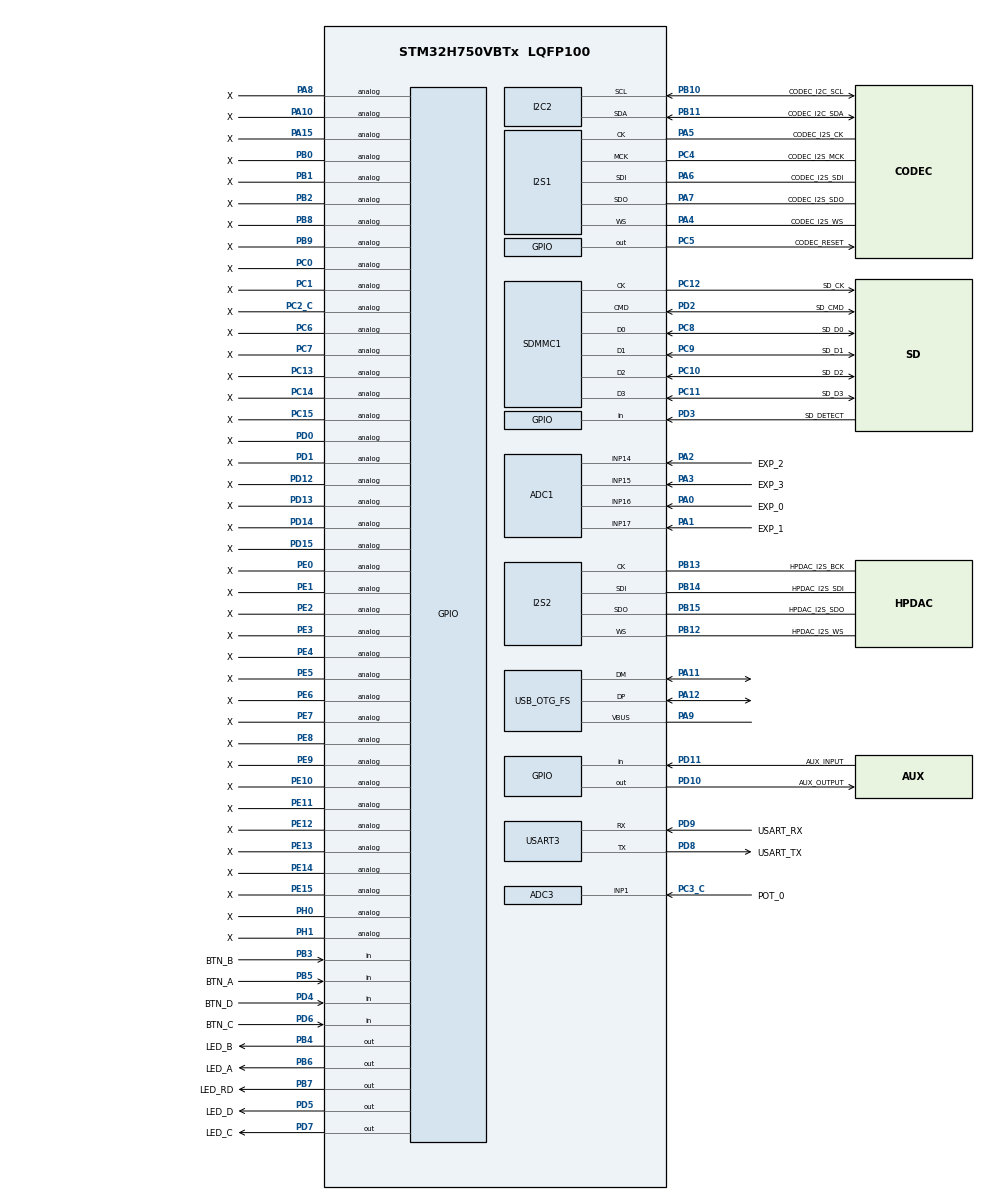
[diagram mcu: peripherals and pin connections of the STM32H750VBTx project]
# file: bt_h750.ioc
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ADC1.Channel-0\#ChannelRegularConversion=ADC_CHANNEL_14
ADC1.Channel-1\#ChannelRegularConversion=ADC_CHANNEL_15
ADC1.Channel-2\#ChannelRegularConversion=ADC_CHANNEL_16
ADC1.Channel-3\#ChannelRegularConversion=ADC_CHANNEL_17
ADC1.ClockPrescaler=ADC_CLOCK_ASYNC_DIV4
ADC1.ConversionDataManagement=ADC_CONVERSIONDATA_DMA_CIRCULAR
ADC1.ExternalTrigConv=ADC_EXTERNALTRIG_T2_TRGO
ADC1.NbrOfConversion=4
ADC1.NbrOfConversionFlag=1
ADC1.OffsetNumber-0\#ChannelRegularConversion=ADC_OFFSET_NONE
ADC1.OffsetNumber-1\#ChannelRegularConversion=ADC_OFFSET_NONE
ADC1.OffsetNumber-2\#ChannelRegularConversion=ADC_OFFSET_NONE
ADC1.OffsetNumber-3\#ChannelRegularConversion=ADC_OFFSET_NONE
ADC1.OffsetSignedSaturation-0\#ChannelRegularConversion=DISABLE
ADC1.OffsetSignedSaturation-1\#ChannelRegularConversion=DISABLE
ADC1.OffsetSignedSaturation-2\#ChannelRegularConversion=DISABLE
ADC1.OffsetSignedSaturation-3\#ChannelRegularConversion=DISABLE
ADC1.Rank-0\#ChannelRegularConversion=1
ADC1.Rank-1\#ChannelRegularConversion=2
ADC1.Rank-2\#ChannelRegularConversion=3
ADC1.Rank-3\#ChannelRegularConversion=4
ADC1.SamplingTime-0\#ChannelRegularConversion=ADC_SAMPLETIME_387CYCLES_5
ADC1.SamplingTime-1\#ChannelRegularConversion=ADC_SAMPLETIME_387CYCLES_5
ADC1.SamplingTime-2\#ChannelRegularConversion=ADC_SAMPLETIME_387CYCLES_5
ADC1.SamplingTime-3\#ChannelRegularConversion=ADC_SAMPLETIME_387CYCLES_5
ADC1.master=1
ADC3.Channel-0\#ChannelRegularConversion=ADC_CHANNEL_1
ADC3.ClockPrescaler=ADC_CLOCK_ASYNC_DIV4
ADC3.NbrOfConversionFlag=1
ADC3.OffsetNumber-0\#ChannelRegularConversion=ADC_OFFSET_NONE
ADC3.OffsetSignedSaturation-0\#ChannelRegularConversion=DISABLE
ADC3.Rank-0\#ChannelRegularConversion=1
ADC3.SamplingTime-0\#ChannelRegularConversion=ADC_SAMPLETIME_1CYCLE_5
CORTEX_M7.default_mode_Activation=1
Dma.ADC1.3.Direction=DMA_PERIPH_TO_MEMORY
Dma.ADC1.3.EventEnable=DISABLE
Dma.ADC1.3.FIFOMode=DMA_FIFOMODE_DISABLE
Dma.ADC1.3.Instance=DMA1_Stream3
Dma.ADC1.3.MemDataAlignment=DMA_MDATAALIGN_HALFWORD
Dma.ADC1.3.MemInc=DMA_MINC_ENABLE
Dma.ADC1.3.Mode=DMA_CIRCULAR
Dma.ADC1.3.PeriphDataAlignment=DMA_PDATAALIGN_HALFWORD
Dma.ADC1.3.PeriphInc=DMA_PINC_DISABLE
Dma.ADC1.3.Polarity=HAL_DMAMUX_REQ_GEN_RISING
Dma.ADC1.3.Priority=DMA_PRIORITY_LOW
Dma.ADC1.3.RequestNumber=1
Dma.ADC1.3.SignalID=NONE
Dma.ADC1.3.SyncEnable=DISABLE
Dma.ADC1.3.SyncPolarity=HAL_DMAMUX_SYNC_NO_EVENT
Dma.ADC1.3.SyncRequestNumber=1
Dma.ADC1.3.SyncSignalID=NONE
Dma.Request0=SPI2_TX
Dma.Request1=SPI1_RX
Dma.Request2=SPI1_TX
Dma.Request3=ADC1
Dma.Request4=USART3_RX
Dma.Request5=USART3_TX
Dma.SPI1_RX.1.Direction=DMA_PERIPH_TO_MEMORY
Dma.SPI1_RX.1.EventEnable=DISABLE
Dma.SPI1_RX.1.FIFOMode=DMA_FIFOMODE_DISABLE
Dma.SPI1_RX.1.Instance=DMA1_Stream1
Dma.SPI1_RX.1.MemDataAlignment=DMA_MDATAALIGN_WORD
Dma.SPI1_RX.1.MemInc=DMA_MINC_ENABLE
Dma.SPI1_RX.1.Mode=DMA_CIRCULAR
Dma.SPI1_RX.1.PeriphDataAlignment=DMA_PDATAALIGN_WORD
Dma.SPI1_RX.1.PeriphInc=DMA_PINC_DISABLE
Dma.SPI1_RX.1.Polarity=HAL_DMAMUX_REQ_GEN_RISING
Dma.SPI1_RX.1.Priority=DMA_PRIORITY_HIGH
Dma.SPI1_RX.1.RequestNumber=1
Dma.SPI1_RX.1.SignalID=NONE
Dma.SPI1_RX.1.SyncEnable=DISABLE
Dma.SPI1_RX.1.SyncPolarity=HAL_DMAMUX_SYNC_NO_EVENT
Dma.SPI1_RX.1.SyncRequestNumber=1
Dma.SPI1_RX.1.SyncSignalID=NONE
Dma.SPI1_TX.2.Direction=DMA_MEMORY_TO_PERIPH
Dma.SPI1_TX.2.EventEnable=DISABLE
Dma.SPI1_TX.2.FIFOMode=DMA_FIFOMODE_DISABLE
Dma.SPI1_TX.2.Instance=DMA1_Stream2
Dma.SPI1_TX.2.MemDataAlignment=DMA_MDATAALIGN_WORD
Dma.SPI1_TX.2.MemInc=DMA_MINC_ENABLE
Dma.SPI1_TX.2.Mode=DMA_CIRCULAR
Dma.SPI1_TX.2.PeriphDataAlignment=DMA_PDATAALIGN_WORD
Dma.SPI1_TX.2.PeriphInc=DMA_PINC_DISABLE
Dma.SPI1_TX.2.Polarity=HAL_DMAMUX_REQ_GEN_RISING
Dma.SPI1_TX.2.Priority=DMA_PRIORITY_HIGH
Dma.SPI1_TX.2.RequestNumber=1
Dma.SPI1_TX.2.SignalID=NONE
Dma.SPI1_TX.2.SyncEnable=DISABLE
Dma.SPI1_TX.2.SyncPolarity=HAL_DMAMUX_SYNC_NO_EVENT
Dma.SPI1_TX.2.SyncRequestNumber=1
Dma.SPI1_TX.2.SyncSignalID=NONE
Dma.SPI2_TX.0.Direction=DMA_MEMORY_TO_PERIPH
Dma.SPI2_TX.0.EventEnable=DISABLE
Dma.SPI2_TX.0.FIFOMode=DMA_FIFOMODE_DISABLE
Dma.SPI2_TX.0.Instance=DMA1_Stream0
Dma.SPI2_TX.0.MemDataAlignment=DMA_MDATAALIGN_WORD
Dma.SPI2_TX.0.MemInc=DMA_MINC_ENABLE
Dma.SPI2_TX.0.Mode=DMA_CIRCULAR
Dma.SPI2_TX.0.PeriphDataAlignment=DMA_PDATAALIGN_WORD
Dma.SPI2_TX.0.PeriphInc=DMA_PINC_DISABLE
Dma.SPI2_TX.0.Polarity=HAL_DMAMUX_REQ_GEN_RISING
Dma.SPI2_TX.0.Priority=DMA_PRIORITY_HIGH
Dma.SPI2_TX.0.RequestNumber=1
Dma.SPI2_TX.0.SignalID=NONE
Dma.SPI2_TX.0.SyncEnable=DISABLE
Dma.SPI2_TX.0.SyncPolarity=HAL_DMAMUX_SYNC_NO_EVENT
Dma.SPI2_TX.0.SyncRequestNumber=1
Dma.SPI2_TX.0.SyncSignalID=NONE
Dma.USART3_RX.4.Direction=DMA_PERIPH_TO_MEMORY
Dma.USART3_RX.4.EventEnable=DISABLE
Dma.USART3_RX.4.FIFOMode=DMA_FIFOMODE_DISABLE
Dma.USART3_RX.4.Instance=DMA1_Stream4
Dma.USART3_RX.4.MemDataAlignment=DMA_MDATAALIGN_WORD
Dma.USART3_RX.4.MemInc=DMA_MINC_ENABLE
Dma.USART3_RX.4.Mode=DMA_CIRCULAR
Dma.USART3_RX.4.PeriphDataAlignment=DMA_PDATAALIGN_WORD
Dma.USART3_RX.4.PeriphInc=DMA_PINC_DISABLE
Dma.USART3_RX.4.Polarity=HAL_DMAMUX_REQ_GEN_RISING
Dma.USART3_RX.4.Priority=DMA_PRIORITY_LOW
Dma.USART3_RX.4.RequestNumber=1
Dma.USART3_RX.4.SignalID=NONE
Dma.USART3_RX.4.SyncEnable=DISABLE
Dma.USART3_RX.4.SyncPolarity=HAL_DMAMUX_SYNC_NO_EVENT
Dma.USART3_RX.4.SyncRequestNumber=1
Dma.USART3_RX.4.SyncSignalID=NONE
Dma.USART3_TX.5.Direction=DMA_MEMORY_TO_PERIPH
Dma.USART3_TX.5.EventEnable=DISABLE
Dma.USART3_TX.5.FIFOMode=DMA_FIFOMODE_DISABLE
Dma.USART3_TX.5.Instance=DMA1_Stream5
Dma.USART3_TX.5.MemDataAlignment=DMA_MDATAALIGN_WORD
Dma.USART3_TX.5.MemInc=DMA_MINC_ENABLE
Dma.USART3_TX.5.Mode=DMA_CIRCULAR
Dma.USART3_TX.5.PeriphDataAlignment=DMA_PDATAALIGN_WORD
Dma.USART3_TX.5.PeriphInc=DMA_PINC_DISABLE
Dma.USART3_TX.5.Polarity=HAL_DMAMUX_REQ_GEN_RISING
Dma.USART3_TX.5.Priority=DMA_PRIORITY_LOW
Dma.USART3_TX.5.RequestNumber=1
Dma.USART3_TX.5.SignalID=NONE
Dma.USART3_TX.5.SyncEnable=DISABLE
Dma.USART3_TX.5.SyncPolarity=HAL_DMAMUX_SYNC_NO_EVENT
Dma.USART3_TX.5.SyncRequestNumber=1
Dma.USART3_TX.5.SyncSignalID=NONE
I2C2.Timing=0x307075B1
I2S1.AudioFreq=I2S_AUDIOFREQ_48K
I2S1.DataFormat=I2S_DATAFORMAT_32B
I2S1.ErrorAudioFreq=1.97 %
I2S1.Instance=SPI$Index
I2S1.RealAudioFreq=48.95 KHz
I2S2.AudioFreq=I2S_AUDIOFREQ_48K
I2S2.DataFormat=I2S_DATAFORMAT_32B
I2S2.ErrorAudioFreq=1.97 %
I2S2.Instance=SPI$Index
I2S2.RealAudioFreq=48.95 KHz
I2S2.Standard=I2S_STANDARD_PHILIPS
Mcu.Family=STM32H7
Mcu.Name=STM32H750VBTx
Mcu.Package=LQFP100
NVIC.DMA1_Stream0_IRQn=true\:0\:0\:false\:false\:true\:false\:true\:true
NVIC.DMA1_Stream1_IRQn=true\:0\:0\:false\:false\:true\:false\:true\:true
NVIC.DMA1_Stream2_IRQn=true\:0\:0\:false\:false\:true\:false\:true\:true
NVIC.DMA1_Stream3_IRQn=true\:0\:0\:false\:false\:true\:false\:true\:true
NVIC.DMA1_Stream4_IRQn=true\:0\:0\:false\:false\:true\:false\:true\:true
NVIC.DMA1_Stream5_IRQn=true\:0\:0\:false\:false\:true\:false\:true\:true
NVIC.OTG_FS_EP1_IN_IRQn=true\:0\:0\:false\:false\:true\:true\:true\:true
NVIC.OTG_FS_EP1_OUT_IRQn=true\:0\:0\:false\:false\:true\:true\:true\:true
NVIC.OTG_FS_IRQn=true\:0\:0\:false\:false\:true\:true\:true\:true
NVIC.PriorityGroup=NVIC_PRIORITYGROUP_4
NVIC.SDMMC1_IRQn=true\:0\:0\:false\:false\:true\:true\:true\:true
NVIC.USART3_IRQn=true\:0\:0\:false\:false\:true\:true\:true\:true
PA0.GPIO_Label=EXP_0
PA0.Mode=IN16-Single-Ended
PA0.Signal=ADC1_INP16
PA1.GPIO_Label=EXP_1
PA1.Mode=IN17-Single-Ended
PA1.Signal=ADC1_INP17
PA10.GPIO_Label=X
PA10.GPIO_Pd=GPIO_PULLDOWN
PA10.Signal=GPIO_Analog
PA11.Mode=Device_Only
PA11.Signal=USB_OTG_FS_DM
PA12.Mode=Device_Only
PA12.Signal=USB_OTG_FS_DP
PA13\ (JTMS/SWDIO).Mode=Serial_Wire
PA13\ (JTMS/SWDIO).Signal=DEBUG_JTMS-SWDIO
PA14\ (JTCK/SWCLK).Mode=Serial_Wire
PA14\ (JTCK/SWCLK).Signal=DEBUG_JTCK-SWCLK
PA15\ (JTDI).GPIO_Label=X
PA15\ (JTDI).GPIO_Pd=GPIO_PULLDOWN
PA15\ (JTDI).Signal=GPIO_Analog
PA2.GPIO_Label=EXP_2
PA2.Signal=ADCx_INP14
PA3.GPIO_Label=EXP_3
PA3.Signal=ADCx_INP15
PA4.GPIO_Label=CODEC_I2S_WS
PA4.Mode=Full_Duplex_Master
PA4.Signal=I2S1_WS
PA5.GPIO_Label=CODEC_I2S_CK
PA5.Mode=Full_Duplex_Master
PA5.Signal=I2S1_CK
PA6.GPIO_Label=CODEC_I2S_SDI
PA6.Mode=Full_Duplex_Master
PA6.Signal=I2S1_SDI
PA7.GPIO_Label=CODEC_I2S_SDO
PA7.Mode=Full_Duplex_Master
PA7.Signal=I2S1_SDO
PA8.GPIO_Label=X
PA8.GPIO_Pd=GPIO_PULLDOWN
PA8.Signal=GPIO_Analog
PA9.Mode=Activate_VBUS
PA9.Signal=USB_OTG_FS_VBUS
PB0.GPIO_Label=X
PB0.GPIO_Pd=GPIO_PULLDOWN
PB0.Signal=GPIO_Analog
PB1.GPIO_Label=X
PB1.GPIO_Pd=GPIO_PULLDOWN
PB1.Signal=GPIO_Analog
PB10.GPIO_Label=CODEC_I2C_SCL
PB10.GPIO_Pu=GPIO_NOPULL
PB10.GPIO_Speed=GPIO_SPEED_FREQ_LOW
PB10.Mode=I2C
PB10.Signal=I2C2_SCL
PB11.GPIO_Label=CODEC_I2C_SDA
PB11.GPIO_Pu=GPIO_NOPULL
PB11.GPIO_Speed=GPIO_SPEED_FREQ_LOW
PB11.Mode=I2C
PB11.Signal=I2C2_SDA
PB12.GPIO_Label=HPDAC_I2S_WS
PB12.GPIO_Speed=GPIO_SPEED_FREQ_LOW
PB12.Mode=Full_Duplex_Master
PB12.Signal=I2S2_WS
PB13.GPIO_Label=HPDAC_I2S_BCK
PB13.GPIO_Speed=GPIO_SPEED_FREQ_LOW
PB13.Mode=Full_Duplex_Master
PB13.Signal=I2S2_CK
PB14.GPIO_Label=HPDAC_I2S_SDI
PB14.GPIO_Speed=GPIO_SPEED_FREQ_LOW
PB14.Mode=Full_Duplex_Master
PB14.Signal=I2S2_SDI
PB15.GPIO_Label=HPDAC_I2S_SDO
PB15.GPIO_Speed=GPIO_SPEED_FREQ_LOW
PB15.Mode=Full_Duplex_Master
PB15.Signal=I2S2_SDO
PB2.GPIO_Label=X
PB2.GPIO_Pd=GPIO_PULLDOWN
PB2.Signal=GPIO_Analog
PB3\ (JTDO/TRACESWO).GPIO_Label=BTN_B
PB3\ (JTDO/TRACESWO).Signal=GPIO_Input
PB4\ (NJTRST).GPIO_Label=LED_B
PB4\ (NJTRST).Signal=GPIO_Output
PB5.GPIO_Label=BTN_A
PB5.Signal=GPIO_Input
PB6.GPIO_Label=LED_A
PB6.Signal=GPIO_Output
PB7.GPIO_Label=LED_RD
PB7.Signal=GPIO_Output
PB8.GPIO_Label=X
PB8.GPIO_Pd=GPIO_PULLDOWN
PB8.Signal=GPIO_Analog
PB9.GPIO_Label=X
PB9.GPIO_Pd=GPIO_PULLDOWN
PB9.Signal=GPIO_Analog
PC0.GPIO_Label=X
PC0.GPIO_Pd=GPIO_PULLDOWN
PC0.Signal=GPIO_Analog
PC1.GPIO_Label=X
PC1.GPIO_Pd=GPIO_PULLDOWN
PC1.Signal=GPIO_Analog
PC10.GPIO_Label=SD_D2
PC10.GPIO_PuPd=GPIO_PULLUP
PC10.GPIO_Speed_High_Default=GPIO_SPEED_FREQ_LOW
PC10.Mode=SD_4_bits_Wide_bus
PC10.Signal=SDMMC1_D2
PC11.GPIO_Label=SD_D3
PC11.GPIO_PuPd=GPIO_PULLUP
PC11.GPIO_Speed_High_Default=GPIO_SPEED_FREQ_LOW
PC11.Mode=SD_4_bits_Wide_bus
PC11.Signal=SDMMC1_D3
PC12.GPIO_Label=SD_CK
PC12.GPIO_Speed_High_Default=GPIO_SPEED_FREQ_LOW
PC12.Mode=SD_4_bits_Wide_bus
PC12.Signal=SDMMC1_CK
PC13.GPIO_Label=X
PC13.GPIO_Pd=GPIO_PULLDOWN
PC13.Signal=GPIO_Analog
PC14-OSC32_IN\ (OSC32_IN).GPIO_Label=X
PC14-OSC32_IN\ (OSC32_IN).GPIO_Pd=GPIO_PULLDOWN
PC14-OSC32_IN\ (OSC32_IN).Signal=GPIO_Analog
PC15-OSC32_OUT\ (OSC32_OUT).GPIO_Label=X
PC15-OSC32_OUT\ (OSC32_OUT).GPIO_Pd=GPIO_PULLDOWN
PC15-OSC32_OUT\ (OSC32_OUT).Signal=GPIO_Analog
PC2_C.GPIO_Label=X
PC2_C.GPIO_Pd=GPIO_PULLDOWN
PC2_C.Signal=GPIO_Analog
PC3_C.GPIO_Label=POT_0
PC3_C.Mode=IN1-Single-Ended
PC3_C.Signal=ADC3_INP1
PC4.GPIO_Label=CODEC_I2S_MCK
PC4.Mode=Master_Clock_Activated
PC4.Signal=I2S1_MCK
PC5.GPIO_Label=CODEC_RESET
PC5.Signal=GPIO_Output
PC6.GPIO_Label=X
PC6.GPIO_Pd=GPIO_PULLDOWN
PC6.Signal=GPIO_Analog
PC7.GPIO_Label=X
PC7.GPIO_Pd=GPIO_PULLDOWN
PC7.Signal=GPIO_Analog
PC8.GPIO_Label=SD_D0
PC8.GPIO_PuPd=GPIO_PULLUP
PC8.GPIO_Speed_High_Default=GPIO_SPEED_FREQ_LOW
PC8.Mode=SD_4_bits_Wide_bus
PC8.Signal=SDMMC1_D0
PC9.GPIO_Label=SD_D1
PC9.GPIO_PuPd=GPIO_PULLUP
PC9.GPIO_Speed_High_Default=GPIO_SPEED_FREQ_LOW
PC9.Mode=SD_4_bits_Wide_bus
PC9.Signal=SDMMC1_D1
PD0.GPIO_Label=X
PD0.GPIO_Pd=GPIO_PULLDOWN
PD0.Signal=GPIO_Analog
PD1.GPIO_Label=X
PD1.GPIO_Pd=GPIO_PULLDOWN
PD1.Signal=GPIO_Analog
PD10.GPIO_Label=AUX_OUTPUT
PD10.Signal=GPIO_Output
PD11.GPIO_Label=AUX_INPUT
PD11.Signal=GPIO_Input
PD12.GPIO_Label=X
PD12.GPIO_Pd=GPIO_PULLDOWN
PD12.Signal=GPIO_Analog
PD13.GPIO_Label=X
PD13.GPIO_Pd=GPIO_PULLDOWN
PD13.Signal=GPIO_Analog
PD14.GPIO_Label=X
PD14.GPIO_Pd=GPIO_PULLDOWN
PD14.Signal=GPIO_Analog
PD15.GPIO_Label=X
PD15.GPIO_Pd=GPIO_PULLDOWN
PD15.Signal=GPIO_Analog
PD2.GPIO_Label=SD_CMD
PD2.GPIO_PuPd=GPIO_PULLUP
PD2.GPIO_Speed_High_Default=GPIO_SPEED_FREQ_LOW
PD2.Mode=SD_4_bits_Wide_bus
PD2.Signal=SDMMC1_CMD
PD3.GPIO_Label=SD_DETECT
PD3.Signal=GPIO_Input
PD4.GPIO_Label=BTN_D
PD4.Signal=GPIO_Input
PD5.GPIO_Label=LED_D
PD5.Signal=GPIO_Output
PD6.GPIO_Label=BTN_C
PD6.Signal=GPIO_Input
PD7.GPIO_Label=LED_C
PD7.Signal=GPIO_Output
PD8.GPIO_Label=USART_TX
PD8.Mode=Asynchronous
PD8.Signal=USART3_TX
PD9.GPIO_Label=USART_RX
PD9.Mode=Asynchronous
PD9.Signal=USART3_RX
PE0.GPIO_Label=X
PE0.GPIO_Pd=GPIO_PULLDOWN
PE0.Signal=GPIO_Analog
PE1.GPIO_Label=X
PE1.GPIO_Pd=GPIO_PULLDOWN
PE1.Signal=GPIO_Analog
PE10.GPIO_Label=X
PE10.GPIO_Pd=GPIO_PULLDOWN
PE10.Signal=GPIO_Analog
PE11.GPIO_Label=X
PE11.GPIO_Pd=GPIO_PULLDOWN
PE11.Signal=GPIO_Analog
PE12.GPIO_Label=X
PE12.GPIO_Pd=GPIO_PULLDOWN
PE12.Signal=GPIO_Analog
PE13.GPIO_Label=X
PE13.GPIO_Pd=GPIO_PULLDOWN
PE13.Signal=GPIO_Analog
PE14.GPIO_Label=X
PE14.GPIO_Pd=GPIO_PULLDOWN
PE14.Signal=GPIO_Analog
PE15.GPIO_Label=X
PE15.GPIO_Pd=GPIO_PULLDOWN
PE15.Signal=GPIO_Analog
PE2.GPIO_Label=X
PE2.GPIO_Pd=GPIO_PULLDOWN
PE2.Signal=GPIO_Analog
PE3.GPIO_Label=X
PE3.GPIO_Pd=GPIO_PULLDOWN
PE3.Signal=GPIO_Analog
PE4.GPIO_Label=X
PE4.GPIO_Pd=GPIO_PULLDOWN
PE4.Signal=GPIO_Analog
PE5.GPIO_Label=X
PE5.GPIO_Pd=GPIO_PULLDOWN
PE5.Signal=GPIO_Analog
PE6.GPIO_Label=X
PE6.GPIO_Pd=GPIO_PULLDOWN
PE6.Signal=GPIO_Analog
PE7.GPIO_Label=X
PE7.GPIO_Pd=GPIO_PULLDOWN
PE7.Signal=GPIO_Analog
PE8.GPIO_Label=X
PE8.GPIO_Pd=GPIO_PULLDOWN
PE8.Signal=GPIO_Analog
PE9.GPIO_Label=X
PE9.GPIO_Pd=GPIO_PULLDOWN
PE9.Signal=GPIO_Analog
PH0-OSC_IN\ (PH0).GPIO_Label=X
PH0-OSC_IN\ (PH0).GPIO_Pd=GPIO_PULLDOWN
PH0-OSC_IN\ (PH0).Signal=GPIO_Analog
PH1-OSC_OUT\ (PH1).GPIO_Label=X
PH1-OSC_OUT\ (PH1).GPIO_Pd=GPIO_PULLDOWN
PH1-OSC_OUT\ (PH1).Signal=GPIO_Analog
ProjectManager.HeapSize=0x200
ProjectManager.StackSize=0x400
ProjectManager.TargetToolchain=CMake
RCC.ADCFreq_Value=75187500
RCC.APB1Freq_Value=120000000
RCC.APB2Freq_Value=120000000
RCC.APB3Freq_Value=120000000
RCC.APB4Freq_Value=120000000
RCC.CortexFreq_Value=480000000
RCC.D1PPRE=RCC_APB3_DIV2
RCC.D2PPRE1=RCC_APB1_DIV2
RCC.D2PPRE2=RCC_APB2_DIV2
RCC.D3PPRE=RCC_APB4_DIV2
RCC.DIVM1=1
RCC.DIVM2=4
RCC.DIVN1=240
RCC.DIVN2=150
RCC.HCLKFreq_Value=240000000
RCC.HPRE=RCC_HCLK_DIV2
RCC.PLL2FRACN=3072
RCC.PLLFRACN=0
RCC.PLLSourceVirtual=RCC_PLLSOURCE_CSI
RCC.PWR_Regulator_Voltage_Scale=PWR_REGULATOR_VOLTAGE_SCALE0
RCC.SDMMC1CLockSelection=RCC_SDMMCCLKSOURCE_PLL2
RCC.SPI123CLockSelection=RCC_SPI123CLKSOURCE_PLL2
RCC.SYSCLKFreq_VALUE=480000000
RCC.SYSCLKSource=RCC_SYSCLKSOURCE_PLLCLK
RCC.Tim2Mul=2
RCC.USBCLockSelection=RCC_USBCLKSOURCE_HSI48
RCC.USBFreq_Value=48000000
SDMMC1.ClockDiv=4
SH.ADCx_INP14.0=ADC1_INP14,IN14-Single-Ended
SH.ADCx_INP15.0=ADC1_INP15,IN15-Single-Ended
TIM2.Channel-PWM\ Generation1\ No\ Output=TIM_CHANNEL_1
TIM2.Period=2048-1
TIM2.Prescaler=2048-1
TIM2.TIM_MasterOutputTrigger=TIM_TRGO_UPDATE
USART3.VirtualMode-Asynchronous=VM_ASYNC
USB_OTG_FS.VirtualMode=Device_Only
VP_MEMORYMAP_VS_MEMORYMAP.Mode=CurAppReg
VP_TIM2_VS_ClockSourceINT.Mode=Internal
VP_TIM2_VS_no_output1.Mode=PWM Generation1 No Output
board=custom

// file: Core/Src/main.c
/* USER CODE BEGIN Header */
/**
  ******************************************************************************
  * @file           : main.c
  * @brief          : Main program body
  ******************************************************************************
  * @attention
  *
  * Copyright (c) 2026 STMicroelectronics.
  * All rights reserved.
  *
  * This software is licensed under terms that can be found in the LICENSE file
  * in the root directory of this software component.
  * If no LICENSE file comes with this software, it is provided AS-IS.
  *
  ******************************************************************************
  */
/* USER CODE END Header */
#include "main.h"

/* USER CODE BEGIN Includes */
#include <string.h>

/* USER CODE END Includes */

/* USER CODE BEGIN PD */
#define HP_BUFFER_SIZE 512
#define HP_BLOCK_SIZE (HP_BUFFER_SIZE / 2)
#define HP_SR_F 48950.0f
#define HP_SR_I 48950

#define CODEC_BUFFER_SIZE 512
#define CODEC_BLOCK_SIZE (CODEC_BUFFER_SIZE / 2)
#define CODEC_SR_F 48950.0f
#define CODEC_SR_I 48950

#define FLOAT_TO_INT16 (32768.0f)
#define INT16_TO_FLOAT (1.0f / 32768.0f)
#define FLOAT_TO_INT32 (2147483648.0f)
#define INT32_TO_FLOAT (1.0f / 2147483648.0f)

#define PI 3.14159265f
#define STARTUP_RAMP_MS 100U
#define STARTUP_RAMP_SAMPLES ((uint32_t)(HP_SR_F * STARTUP_RAMP_MS / 1000.0f))

/* USER CODE END PD */

ADC_HandleTypeDef hadc1;
ADC_HandleTypeDef hadc3;
DMA_HandleTypeDef hdma_adc1;

I2C_HandleTypeDef hi2c2;

I2S_HandleTypeDef hi2s1;
I2S_HandleTypeDef hi2s2;
DMA_HandleTypeDef hdma_spi1_rx;
DMA_HandleTypeDef hdma_spi1_tx;
DMA_HandleTypeDef hdma_spi2_tx;

SD_HandleTypeDef hsd1;

TIM_HandleTypeDef htim2;

UART_HandleTypeDef huart3;
DMA_HandleTypeDef hdma_usart3_rx;
DMA_HandleTypeDef hdma_usart3_tx;

PCD_HandleTypeDef hpcd_USB_OTG_FS;

/* USER CODE BEGIN PV */
CS4282P_HandleTypeDef hcs4282p;

/* DMA1 cannot access DTCMRAM, so this buffer must live in AXI SRAM (see .dma_buffer in the linker script) */

/* TO PUT ON LINE ~233. DMA-accessible buffers: DTCMRAM is not reachable by DMA1/DMA2 on STM32H7, so place these in AXI SRAM instead */
/*.dma_buffer (NOLOAD) :
{
  . = ALIGN(4);
  *(.dma_buffer)
  *(.dma_buffer*)
  . = ALIGN(4);
} >RAM*/

__attribute__((section(".dma_buffer"))) int32_t hpDacData[HP_BUFFER_SIZE];
static volatile int32_t* hpOutBuf = &hpDacData[0];
uint8_t hpDataReady = 0;

__attribute__((section(".dma_buffer"))) int32_t codecDacData[CODEC_BUFFER_SIZE];
static volatile int32_t* codecOutBuf = &codecDacData[0];
uint8_t codecOutDataReady = 0;

__attribute__((section(".dma_buffer"))) int32_t codecAdcData[CODEC_BUFFER_SIZE];
static volatile int32_t* codecInBuf = &codecAdcData[0];
uint8_t codecInDataReady = 0;

__attribute__((section(".dma_buffer"))) uint16_t expData[4] = {1, 2, 3, 4};

/* USER CODE END PV */

void SystemClock_Config(void);
void PeriphCommonClock_Config(void);
static void MPU_Config(void);
static void MX_GPIO_Init(void);
static void MX_DMA_Init(void);
static void MX_ADC1_Init(void);
static void MX_USB_OTG_FS_PCD_Init(void);
static void MX_I2C2_Init(void);
static void MX_I2S1_Init(void);
static void MX_I2S2_Init(void);
static void MX_SDMMC1_SD_Init(void);
static void MX_USART3_UART_Init(void);
static void MX_ADC3_Init(void);
static void MX_TIM2_Init(void);
/* USER CODE BEGIN PFP */
// https://youtu.be/zlGSxZGwj-E?t=823

/* USER CODE END PFP */

/* USER CODE BEGIN 0 */
void HAL_I2S_TxCpltCallback(I2S_HandleTypeDef *hi2s) {
  if (hi2s == &hi2s2) {
    hpOutBuf = &hpDacData[HP_BLOCK_SIZE];
    hpDataReady = 1;
  }
}

void HAL_I2S_TxHalfCpltCallback(I2S_HandleTypeDef *hi2s) {
  if (hi2s == &hi2s2) {
    hpOutBuf = &hpDacData[0];
    hpDataReady = 1;
  }
}

void HAL_I2SEx_TxRxCpltCallback(I2S_HandleTypeDef *hi2s) {
  if (hi2s == &hi2s1) {
    codecInBuf = &codecAdcData[CODEC_BLOCK_SIZE];
    codecInDataReady = 1;
    codecOutBuf = &codecDacData[CODEC_BLOCK_SIZE];
    codecOutDataReady = 1;
  }
}

void HAL_I2SEx_TxRxHalfCpltCallback(I2S_HandleTypeDef *hi2s) {
  if (hi2s == &hi2s1) {
    codecInBuf = &codecAdcData[0];
    codecInDataReady = 1;
    codecOutBuf = &codecDacData[0];
    codecOutDataReady = 1;
  }
}

void HAL_I2S_ErrorCallback(I2S_HandleTypeDef *hi2s) {
  if (hi2s->ErrorCode != HAL_I2S_ERROR_NONE) {
    Error_Handler();
  }
}

void HAL_I2SEx_ErrorCallback(I2S_HandleTypeDef *hi2s) {
  if (hi2s->ErrorCode != HAL_I2S_ERROR_NONE) {
    Error_Handler();
  }
}

void processHpData() {
  static uint32_t sample = 0;
  static float gain, sine, leftOut, rightOut, ramp;
  for (uint32_t i = 0; i < HP_BLOCK_SIZE; i += 2) {
    ramp = sample < STARTUP_RAMP_SAMPLES
      ? (float)sample / (float)STARTUP_RAMP_SAMPLES
      : 1.0f;
    gain = 0.02f;
    sine = sinf(2.f * PI * 440.f * (float)sample / HP_SR_F) * gain;
    leftOut = sine * ramp;
    rightOut = sine * ramp;
    hpOutBuf[i] = (int32_t)(FLOAT_TO_INT32 * leftOut);
    hpOutBuf[i+1] = (int32_t)(FLOAT_TO_INT32 * rightOut);
    sample++;
  }
  sample %= HP_SR_I;
}

static volatile uint32_t codecBusy = 0;

void processCodecData() {
  uint32_t codecStart = HAL_GetTick();
  static uint32_t sample = 0;
  static float gain, sine, leftOut, rightOut, ramp;
  for (uint32_t i = 0; i < CODEC_BLOCK_SIZE; i += 2) {
    ramp = sample < STARTUP_RAMP_SAMPLES
      ? (float)sample / (float)STARTUP_RAMP_SAMPLES
      : 1.0f;
    gain = 0.2f;
    sine = sinf(2.f * PI * 440.f * (float)sample / CODEC_SR_F) * gain;
    leftOut = sine * ramp;
    rightOut = sine * ramp;
    codecOutBuf[i] = (int32_t)(FLOAT_TO_INT32 * leftOut); // this doesnt
    codecOutBuf[i+1] = (int32_t)(FLOAT_TO_INT32 * rightOut); // this channel works
    //codecOutBuf[i] = codecInBuf[i];
    //codecOutBuf[i+1] = codecInBuf[i+1];
    sample++;
  }
  sample %= CODEC_SR_I;
  codecBusy = HAL_GetTick() - codecStart;
}

/* USER CODE END 0 */

int main(void)
{

  /* MPU Configuration--------------------------------------------------------*/
  MPU_Config();

  /* MCU Configuration--------------------------------------------------------*/

  /* Reset of all peripherals, Initializes the Flash interface and the Systick. */
  HAL_Init();

  /* Configure the system clock */
  SystemClock_Config();

  /* Configure the peripherals common clocks */
  PeriphCommonClock_Config();

  /* Initialize all configured peripherals */
  MX_GPIO_Init();
  MX_DMA_Init();
  MX_ADC1_Init();
  MX_USB_OTG_FS_PCD_Init();
  MX_I2C2_Init();
  MX_I2S1_Init();
  MX_I2S2_Init();
  MX_SDMMC1_SD_Init();
  MX_USART3_UART_Init();
  MX_ADC3_Init();
  MX_TIM2_Init();
  /* USER CODE BEGIN 2 */
  HAL_SD_CardInfoTypeDef CardInfo;
  if (HAL_SD_GetCardInfo(&hsd1, &CardInfo) != HAL_OK) {
    Error_Handler();
  }

  memset(hpDacData, 0, sizeof(hpDacData));
  memset(codecDacData, 0, sizeof(codecDacData));
  memset(codecAdcData, 0, sizeof(codecAdcData));
  HAL_I2S_Transmit_DMA(&hi2s2, (uint16_t*)hpDacData,HP_BUFFER_SIZE);
  HAL_I2SEx_TransmitReceive_DMA(&hi2s1, (const uint16_t *)codecDacData, (uint16_t *)codecAdcData, CODEC_BUFFER_SIZE);

  HAL_StatusTypeDef codecStatus = CS4282P_Init(&hcs4282p, &hi2c2, &hi2s1, CODEC_RESET_GPIO_Port, CODEC_RESET_Pin);
  if (codecStatus != HAL_OK) {
    Error_Handler();
  }

  if (HAL_ADC_Start_DMA(&hadc1, (uint32_t*)expData, 4) != HAL_OK) {
    Error_Handler();
  }
  if (HAL_TIM_Base_Start(&htim2) != HAL_OK) {
    Error_Handler();
  }

  HAL_Delay(1000); // Give some time for the codec PLL to stabilize after init

  uint32_t tick = 0;

  /* USER CODE END 2 */

  /* Infinite loop */
  while (1)
  {

    /* USER CODE BEGIN 3 */
    tick = HAL_GetTick();
    if (tick % 1000 > 500 && tick % 4 == 0) {
      HAL_GPIO_WritePin(GPIOB, LED_A_Pin | LED_B_Pin, GPIO_PIN_SET);
      HAL_GPIO_WritePin(GPIOD, LED_C_Pin | LED_D_Pin, GPIO_PIN_SET);
    } else {
      HAL_GPIO_WritePin(GPIOB, LED_A_Pin | LED_B_Pin, GPIO_PIN_RESET);
      HAL_GPIO_WritePin(GPIOD, LED_C_Pin | LED_D_Pin, GPIO_PIN_RESET);
    }

    if (hpDataReady) {
      processHpData();
      hpDataReady = 0;
    }

    if (codecInDataReady) {
      processCodecData();
      codecInDataReady = 0;
    }

    /*sd_detect = HAL_GPIO_ReadPin(SD_DETECT_GPIO_Port, SD_DETECT_Pin);
    if (sd_detect == GPIO_PIN_RESET) {
      HAL_SD_WriteBlocks(&hsd1, pData, BlockAdd, NumberOfBlocks, Timeout);
    }

    pData[0]++; // Example modification to the data buffer

    if (sd_detect == GPIO_PIN_RESET) {
      HAL_SD_ReadBlocks(&hsd1, pData, BlockAdd, NumberOfBlocks, Timeout);
    }*/

    //HAL_GPIO_TogglePin(GPIOB, LED_RD_Pin | LED_A_Pin | LED_B_Pin);
    //HAL_GPIO_TogglePin(GPIOD, LED_C_Pin | LED_D_Pin);
    //HAL_Delay(500);
  }
  /* USER CODE END 3 */
}

void SystemClock_Config(void)
{
  RCC_OscInitTypeDef RCC_OscInitStruct = {0};
  RCC_ClkInitTypeDef RCC_ClkInitStruct = {0};

  /** Supply configuration update enable
  */
  HAL_PWREx_ConfigSupply(PWR_LDO_SUPPLY);

  /** Configure the main internal regulator output voltage
  */
  __HAL_PWR_VOLTAGESCALING_CONFIG(PWR_REGULATOR_VOLTAGE_SCALE0);

  while(!__HAL_PWR_GET_FLAG(PWR_FLAG_VOSRDY)) {}

  /** Initializes the RCC Oscillators according to the specified parameters
  * in the RCC_OscInitTypeDef structure.
  */
  RCC_OscInitStruct.OscillatorType = RCC_OSCILLATORTYPE_HSI48|RCC_OSCILLATORTYPE_CSI;
  RCC_OscInitStruct.HSI48State = RCC_HSI48_ON;
  RCC_OscInitStruct.CSIState = RCC_CSI_ON;
  RCC_OscInitStruct.CSICalibrationValue = RCC_CSICALIBRATION_DEFAULT;
  RCC_OscInitStruct.PLL.PLLState = RCC_PLL_ON;
  RCC_OscInitStruct.PLL.PLLSource = RCC_PLLSOURCE_CSI;
  RCC_OscInitStruct.PLL.PLLM = 1;
  RCC_OscInitStruct.PLL.PLLN = 240;
  RCC_OscInitStruct.PLL.PLLP = 2;
  RCC_OscInitStruct.PLL.PLLQ = 2;
  RCC_OscInitStruct.PLL.PLLR = 2;
  RCC_OscInitStruct.PLL.PLLRGE = RCC_PLL1VCIRANGE_2;
  RCC_OscInitStruct.PLL.PLLVCOSEL = RCC_PLL1VCOWIDE;
  RCC_OscInitStruct.PLL.PLLFRACN = 0;
  if (HAL_RCC_OscConfig(&RCC_OscInitStruct) != HAL_OK)
  {
    Error_Handler();
  }

  /** Initializes the CPU, AHB and APB buses clocks
  */
  RCC_ClkInitStruct.ClockType = RCC_CLOCKTYPE_HCLK|RCC_CLOCKTYPE_SYSCLK
                              |RCC_CLOCKTYPE_PCLK1|RCC_CLOCKTYPE_PCLK2
                              |RCC_CLOCKTYPE_D3PCLK1|RCC_CLOCKTYPE_D1PCLK1;
  RCC_ClkInitStruct.SYSCLKSource = RCC_SYSCLKSOURCE_PLLCLK;
  RCC_ClkInitStruct.SYSCLKDivider = RCC_SYSCLK_DIV1;
  RCC_ClkInitStruct.AHBCLKDivider = RCC_HCLK_DIV2;
  RCC_ClkInitStruct.APB3CLKDivider = RCC_APB3_DIV2;
  RCC_ClkInitStruct.APB1CLKDivider = RCC_APB1_DIV2;
  RCC_ClkInitStruct.APB2CLKDivider = RCC_APB2_DIV2;
  RCC_ClkInitStruct.APB4CLKDivider = RCC_APB4_DIV2;

  if (HAL_RCC_ClockConfig(&RCC_ClkInitStruct, FLASH_LATENCY_4) != HAL_OK)
  {
    Error_Handler();
  }
}

void PeriphCommonClock_Config(void)
{
  RCC_PeriphCLKInitTypeDef PeriphClkInitStruct = {0};

  /** Initializes the peripherals clock
  */
  PeriphClkInitStruct.PeriphClockSelection = RCC_PERIPHCLK_ADC|RCC_PERIPHCLK_SDMMC
                              |RCC_PERIPHCLK_SPI2|RCC_PERIPHCLK_SPI1;
  PeriphClkInitStruct.PLL2.PLL2M = 4;
  PeriphClkInitStruct.PLL2.PLL2N = 150;
  PeriphClkInitStruct.PLL2.PLL2P = 2;
  PeriphClkInitStruct.PLL2.PLL2Q = 2;
  PeriphClkInitStruct.PLL2.PLL2R = 2;
  PeriphClkInitStruct.PLL2.PLL2RGE = RCC_PLL2VCIRANGE_0;
  PeriphClkInitStruct.PLL2.PLL2VCOSEL = RCC_PLL2VCOMEDIUM;
  PeriphClkInitStruct.PLL2.PLL2FRACN = 3072;
  PeriphClkInitStruct.SdmmcClockSelection = RCC_SDMMCCLKSOURCE_PLL2;
  PeriphClkInitStruct.Spi123ClockSelection = RCC_SPI123CLKSOURCE_PLL2;
  PeriphClkInitStruct.AdcClockSelection = RCC_ADCCLKSOURCE_PLL2;
  if (HAL_RCCEx_PeriphCLKConfig(&PeriphClkInitStruct) != HAL_OK)
  {
    Error_Handler();
  }
}

static void MX_ADC1_Init(void)
{

  ADC_MultiModeTypeDef multimode = {0};
  ADC_ChannelConfTypeDef sConfig = {0};

  /** Common config
  */
  hadc1.Instance = ADC1;
  hadc1.Init.ClockPrescaler = ADC_CLOCK_ASYNC_DIV4;
  hadc1.Init.Resolution = ADC_RESOLUTION_16B;
  hadc1.Init.ScanConvMode = ADC_SCAN_ENABLE;
  hadc1.Init.EOCSelection = ADC_EOC_SINGLE_CONV;
  hadc1.Init.LowPowerAutoWait = DISABLE;
  hadc1.Init.ContinuousConvMode = DISABLE;
  hadc1.Init.NbrOfConversion = 4;
  hadc1.Init.DiscontinuousConvMode = DISABLE;
  hadc1.Init.ExternalTrigConv = ADC_EXTERNALTRIG_T2_TRGO;
  hadc1.Init.ExternalTrigConvEdge = ADC_EXTERNALTRIGCONVEDGE_RISING;
  hadc1.Init.ConversionDataManagement = ADC_CONVERSIONDATA_DMA_CIRCULAR;
  hadc1.Init.Overrun = ADC_OVR_DATA_PRESERVED;
  hadc1.Init.LeftBitShift = ADC_LEFTBITSHIFT_NONE;
  hadc1.Init.OversamplingMode = DISABLE;
  hadc1.Init.Oversampling.Ratio = 1;
  if (HAL_ADC_Init(&hadc1) != HAL_OK)
  {
    Error_Handler();
  }

  /** Configure the ADC multi-mode
  */
  multimode.Mode = ADC_MODE_INDEPENDENT;
  if (HAL_ADCEx_MultiModeConfigChannel(&hadc1, &multimode) != HAL_OK)
  {
    Error_Handler();
  }

  /** Configure Regular Channel
  */
  sConfig.Channel = ADC_CHANNEL_14;
  sConfig.Rank = ADC_REGULAR_RANK_1;
  sConfig.SamplingTime = ADC_SAMPLETIME_387CYCLES_5;
  sConfig.SingleDiff = ADC_SINGLE_ENDED;
  sConfig.OffsetNumber = ADC_OFFSET_NONE;
  sConfig.Offset = 0;
  sConfig.OffsetSignedSaturation = DISABLE;
  if (HAL_ADC_ConfigChannel(&hadc1, &sConfig) != HAL_OK)
  {
    Error_Handler();
  }

  /** Configure Regular Channel
  */
  sConfig.Channel = ADC_CHANNEL_15;
  sConfig.Rank = ADC_REGULAR_RANK_2;
  if (HAL_ADC_ConfigChannel(&hadc1, &sConfig) != HAL_OK)
  {
    Error_Handler();
  }

  /** Configure Regular Channel
  */
  sConfig.Channel = ADC_CHANNEL_16;
  sConfig.Rank = ADC_REGULAR_RANK_3;
  if (HAL_ADC_ConfigChannel(&hadc1, &sConfig) != HAL_OK)
  {
    Error_Handler();
  }

  /** Configure Regular Channel
  */
  sConfig.Channel = ADC_CHANNEL_17;
  sConfig.Rank = ADC_REGULAR_RANK_4;
  if (HAL_ADC_ConfigChannel(&hadc1, &sConfig) != HAL_OK)
  {
    Error_Handler();
  }

}

static void MX_ADC3_Init(void)
{

  ADC_ChannelConfTypeDef sConfig = {0};

  /** Common config
  */
  hadc3.Instance = ADC3;
  hadc3.Init.ClockPrescaler = ADC_CLOCK_ASYNC_DIV4;
  hadc3.Init.Resolution = ADC_RESOLUTION_16B;
  hadc3.Init.ScanConvMode = ADC_SCAN_DISABLE;
  hadc3.Init.EOCSelection = ADC_EOC_SINGLE_CONV;
  hadc3.Init.LowPowerAutoWait = DISABLE;
  hadc3.Init.ContinuousConvMode = DISABLE;
  hadc3.Init.NbrOfConversion = 1;
  hadc3.Init.DiscontinuousConvMode = DISABLE;
  hadc3.Init.ExternalTrigConv = ADC_SOFTWARE_START;
  hadc3.Init.ExternalTrigConvEdge = ADC_EXTERNALTRIGCONVEDGE_NONE;
  hadc3.Init.ConversionDataManagement = ADC_CONVERSIONDATA_DR;
  hadc3.Init.Overrun = ADC_OVR_DATA_PRESERVED;
  hadc3.Init.LeftBitShift = ADC_LEFTBITSHIFT_NONE;
  hadc3.Init.OversamplingMode = DISABLE;
  hadc3.Init.Oversampling.Ratio = 1;
  if (HAL_ADC_Init(&hadc3) != HAL_OK)
  {
    Error_Handler();
  }

  /** Configure Regular Channel
  */
  sConfig.Channel = ADC_CHANNEL_1;
  sConfig.Rank = ADC_REGULAR_RANK_1;
  sConfig.SamplingTime = ADC_SAMPLETIME_1CYCLE_5;
  sConfig.SingleDiff = ADC_SINGLE_ENDED;
  sConfig.OffsetNumber = ADC_OFFSET_NONE;
  sConfig.Offset = 0;
  sConfig.OffsetSignedSaturation = DISABLE;
  if (HAL_ADC_ConfigChannel(&hadc3, &sConfig) != HAL_OK)
  {
    Error_Handler();
  }

}

static void MX_I2C2_Init(void)
{

  hi2c2.Instance = I2C2;
  hi2c2.Init.Timing = 0x307075B1;
  hi2c2.Init.OwnAddress1 = 0;
  hi2c2.Init.AddressingMode = I2C_ADDRESSINGMODE_7BIT;
  hi2c2.Init.DualAddressMode = I2C_DUALADDRESS_DISABLE;
  hi2c2.Init.OwnAddress2 = 0;
  hi2c2.Init.OwnAddress2Masks = I2C_OA2_NOMASK;
  hi2c2.Init.GeneralCallMode = I2C_GENERALCALL_DISABLE;
  hi2c2.Init.NoStretchMode = I2C_NOSTRETCH_DISABLE;
  if (HAL_I2C_Init(&hi2c2) != HAL_OK)
  {
    Error_Handler();
  }

  /** Configure Analogue filter
  */
  if (HAL_I2CEx_ConfigAnalogFilter(&hi2c2, I2C_ANALOGFILTER_ENABLE) != HAL_OK)
  {
    Error_Handler();
  }

  /** Configure Digital filter
  */
  if (HAL_I2CEx_ConfigDigitalFilter(&hi2c2, 0) != HAL_OK)
  {
    Error_Handler();
  }

}

static void MX_I2S1_Init(void)
{

  hi2s1.Instance = SPI1;
  hi2s1.Init.Mode = I2S_MODE_MASTER_FULLDUPLEX;
  hi2s1.Init.Standard = I2S_STANDARD_PHILIPS;
  hi2s1.Init.DataFormat = I2S_DATAFORMAT_32B;
  hi2s1.Init.MCLKOutput = I2S_MCLKOUTPUT_ENABLE;
  hi2s1.Init.AudioFreq = I2S_AUDIOFREQ_48K;
  hi2s1.Init.CPOL = I2S_CPOL_LOW;
  hi2s1.Init.FirstBit = I2S_FIRSTBIT_MSB;
  hi2s1.Init.WSInversion = I2S_WS_INVERSION_DISABLE;
  hi2s1.Init.Data24BitAlignment = I2S_DATA_24BIT_ALIGNMENT_RIGHT;
  hi2s1.Init.MasterKeepIOState = I2S_MASTER_KEEP_IO_STATE_DISABLE;
  if (HAL_I2S_Init(&hi2s1) != HAL_OK)
  {
    Error_Handler();
  }

}

static void MX_I2S2_Init(void)
{

  hi2s2.Instance = SPI2;
  hi2s2.Init.Mode = I2S_MODE_MASTER_FULLDUPLEX;
  hi2s2.Init.Standard = I2S_STANDARD_PHILIPS;
  hi2s2.Init.DataFormat = I2S_DATAFORMAT_32B;
  hi2s2.Init.MCLKOutput = I2S_MCLKOUTPUT_DISABLE;
  hi2s2.Init.AudioFreq = I2S_AUDIOFREQ_48K;
  hi2s2.Init.CPOL = I2S_CPOL_LOW;
  hi2s2.Init.FirstBit = I2S_FIRSTBIT_MSB;
  hi2s2.Init.WSInversion = I2S_WS_INVERSION_DISABLE;
  hi2s2.Init.Data24BitAlignment = I2S_DATA_24BIT_ALIGNMENT_RIGHT;
  hi2s2.Init.MasterKeepIOState = I2S_MASTER_KEEP_IO_STATE_DISABLE;
  if (HAL_I2S_Init(&hi2s2) != HAL_OK)
  {
    Error_Handler();
  }

}

static void MX_SDMMC1_SD_Init(void)
{

  hsd1.Instance = SDMMC1;
  hsd1.Init.ClockEdge = SDMMC_CLOCK_EDGE_RISING;
  hsd1.Init.ClockPowerSave = SDMMC_CLOCK_POWER_SAVE_DISABLE;
  hsd1.Init.BusWide = SDMMC_BUS_WIDE_4B;
  hsd1.Init.HardwareFlowControl = SDMMC_HARDWARE_FLOW_CONTROL_DISABLE;
  hsd1.Init.ClockDiv = 4;
  if (HAL_SD_Init(&hsd1) != HAL_OK)
  {
    Error_Handler();
  }

}

static void MX_TIM2_Init(void)
{

  TIM_ClockConfigTypeDef sClockSourceConfig = {0};
  TIM_MasterConfigTypeDef sMasterConfig = {0};
  TIM_OC_InitTypeDef sConfigOC = {0};

  htim2.Instance = TIM2;
  htim2.Init.Prescaler = 2048-1;
  htim2.Init.CounterMode = TIM_COUNTERMODE_UP;
  htim2.Init.Period = 2048-1;
  htim2.Init.ClockDivision = TIM_CLOCKDIVISION_DIV1;
  htim2.Init.AutoReloadPreload = TIM_AUTORELOAD_PRELOAD_DISABLE;
  if (HAL_TIM_Base_Init(&htim2) != HAL_OK)
  {
    Error_Handler();
  }
  sClockSourceConfig.ClockSource = TIM_CLOCKSOURCE_INTERNAL;
  if (HAL_TIM_ConfigClockSource(&htim2, &sClockSourceConfig) != HAL_OK)
  {
    Error_Handler();
  }
  if (HAL_TIM_PWM_Init(&htim2) != HAL_OK)
  {
    Error_Handler();
  }
  sMasterConfig.MasterOutputTrigger = TIM_TRGO_UPDATE;
  sMasterConfig.MasterSlaveMode = TIM_MASTERSLAVEMODE_DISABLE;
  if (HAL_TIMEx_MasterConfigSynchronization(&htim2, &sMasterConfig) != HAL_OK)
  {
    Error_Handler();
  }
  sConfigOC.OCMode = TIM_OCMODE_PWM1;
  sConfigOC.Pulse = 0;
  sConfigOC.OCPolarity = TIM_OCPOLARITY_HIGH;
  sConfigOC.OCFastMode = TIM_OCFAST_DISABLE;
  if (HAL_TIM_PWM_ConfigChannel(&htim2, &sConfigOC, TIM_CHANNEL_1) != HAL_OK)
  {
    Error_Handler();
  }

}

static void MX_USART3_UART_Init(void)
{

  huart3.Instance = USART3;
  huart3.Init.BaudRate = 115200;
  huart3.Init.WordLength = UART_WORDLENGTH_8B;
  huart3.Init.StopBits = UART_STOPBITS_1;
  huart3.Init.Parity = UART_PARITY_NONE;
  huart3.Init.Mode = UART_MODE_TX_RX;
  huart3.Init.HwFlowCtl = UART_HWCONTROL_NONE;
  huart3.Init.OverSampling = UART_OVERSAMPLING_16;
  huart3.Init.OneBitSampling = UART_ONE_BIT_SAMPLE_DISABLE;
  huart3.Init.ClockPrescaler = UART_PRESCALER_DIV1;
  huart3.AdvancedInit.AdvFeatureInit = UART_ADVFEATURE_NO_INIT;
  if (HAL_UART_Init(&huart3) != HAL_OK)
  {
    Error_Handler();
  }
  if (HAL_UARTEx_SetTxFifoThreshold(&huart3, UART_TXFIFO_THRESHOLD_1_8) != HAL_OK)
  {
    Error_Handler();
  }
  if (HAL_UARTEx_SetRxFifoThreshold(&huart3, UART_RXFIFO_THRESHOLD_1_8) != HAL_OK)
  {
    Error_Handler();
  }
  if (HAL_UARTEx_DisableFifoMode(&huart3) != HAL_OK)
  {
    Error_Handler();
  }

}

static void MX_USB_OTG_FS_PCD_Init(void)
{

  hpcd_USB_OTG_FS.Instance = USB_OTG_FS;
  hpcd_USB_OTG_FS.Init.dev_endpoints = 9;
  hpcd_USB_OTG_FS.Init.speed = PCD_SPEED_FULL;
  hpcd_USB_OTG_FS.Init.dma_enable = DISABLE;
  hpcd_USB_OTG_FS.Init.phy_itface = PCD_PHY_EMBEDDED;
  hpcd_USB_OTG_FS.Init.Sof_enable = DISABLE;
  hpcd_USB_OTG_FS.Init.low_power_enable = DISABLE;
  hpcd_USB_OTG_FS.Init.lpm_enable = DISABLE;
  hpcd_USB_OTG_FS.Init.battery_charging_enable = ENABLE;
  hpcd_USB_OTG_FS.Init.vbus_sensing_enable = ENABLE;
  hpcd_USB_OTG_FS.Init.use_dedicated_ep1 = DISABLE;
  if (HAL_PCD_Init(&hpcd_USB_OTG_FS) != HAL_OK)
  {
    Error_Handler();
  }

}

static void MX_DMA_Init(void)
{

  /* DMA controller clock enable */
  __HAL_RCC_DMA1_CLK_ENABLE();

  /* DMA interrupt init */
  /* DMA1_Stream0_IRQn interrupt configuration */
  HAL_NVIC_SetPriority(DMA1_Stream0_IRQn, 0, 0);
  HAL_NVIC_EnableIRQ(DMA1_Stream0_IRQn);
  /* DMA1_Stream1_IRQn interrupt configuration */
  HAL_NVIC_SetPriority(DMA1_Stream1_IRQn, 0, 0);
  HAL_NVIC_EnableIRQ(DMA1_Stream1_IRQn);
  /* DMA1_Stream2_IRQn interrupt configuration */
  HAL_NVIC_SetPriority(DMA1_Stream2_IRQn, 0, 0);
  HAL_NVIC_EnableIRQ(DMA1_Stream2_IRQn);
  /* DMA1_Stream3_IRQn interrupt configuration */
  HAL_NVIC_SetPriority(DMA1_Stream3_IRQn, 0, 0);
  HAL_NVIC_EnableIRQ(DMA1_Stream3_IRQn);
  /* DMA1_Stream4_IRQn interrupt configuration */
  HAL_NVIC_SetPriority(DMA1_Stream4_IRQn, 0, 0);
  HAL_NVIC_EnableIRQ(DMA1_Stream4_IRQn);
  /* DMA1_Stream5_IRQn interrupt configuration */
  HAL_NVIC_SetPriority(DMA1_Stream5_IRQn, 0, 0);
  HAL_NVIC_EnableIRQ(DMA1_Stream5_IRQn);
  /* DMAMUX1_OVR_IRQn interrupt configuration */
  HAL_NVIC_SetPriority(DMAMUX1_OVR_IRQn, 0, 0);
  HAL_NVIC_EnableIRQ(DMAMUX1_OVR_IRQn);

}

static void MX_GPIO_Init(void)
{
  GPIO_InitTypeDef GPIO_InitStruct = {0};

  /* GPIO Ports Clock Enable */
  __HAL_RCC_GPIOE_CLK_ENABLE();
  __HAL_RCC_GPIOC_CLK_ENABLE();
  __HAL_RCC_GPIOH_CLK_ENABLE();
  __HAL_RCC_GPIOA_CLK_ENABLE();
  __HAL_RCC_GPIOB_CLK_ENABLE();
  __HAL_RCC_GPIOD_CLK_ENABLE();

  /*Configure GPIO pin Output Level */
  HAL_GPIO_WritePin(CODEC_RESET_GPIO_Port, CODEC_RESET_Pin, GPIO_PIN_RESET);

  /*Configure GPIO pin Output Level */
  HAL_GPIO_WritePin(GPIOD, AUX_OUTPUT_Pin|LED_D_Pin|LED_C_Pin, GPIO_PIN_RESET);

  /*Configure GPIO pin Output Level */
  HAL_GPIO_WritePin(GPIOB, LED_B_Pin|LED_A_Pin|LED_RD_Pin, GPIO_PIN_RESET);

  /*Configure GPIO pins : X_Pin XE3_Pin XE4_Pin XE5_Pin
                           XE6_Pin XE7_Pin XE8_Pin XE9_Pin
                           XE10_Pin XE11_Pin XE12_Pin XE13_Pin
                           XE14_Pin XE15_Pin XE0_Pin XE1_Pin */
  GPIO_InitStruct.Pin = X_Pin|XE3_Pin|XE4_Pin|XE5_Pin
                          |XE6_Pin|XE7_Pin|XE8_Pin|XE9_Pin
                          |XE10_Pin|XE11_Pin|XE12_Pin|XE13_Pin
                          |XE14_Pin|XE15_Pin|XE0_Pin|XE1_Pin;
  GPIO_InitStruct.Mode = GPIO_MODE_ANALOG;
  GPIO_InitStruct.Pull = GPIO_PULLDOWN;
  HAL_GPIO_Init(GPIOE, &GPIO_InitStruct);

  /*Configure GPIO pins : XC13_Pin XC14_Pin XC15_Pin XC0_Pin
                           XC1_Pin XC2_Pin XC6_Pin XC7_Pin */
  GPIO_InitStruct.Pin = XC13_Pin|XC14_Pin|XC15_Pin|XC0_Pin
                          |XC1_Pin|XC2_Pin|XC6_Pin|XC7_Pin;
  GPIO_InitStruct.Mode = GPIO_MODE_ANALOG;
  GPIO_InitStruct.Pull = GPIO_PULLDOWN;
  HAL_GPIO_Init(GPIOC, &GPIO_InitStruct);

  /*Configure GPIO pins : XH0_Pin XH1_Pin */
  GPIO_InitStruct.Pin = XH0_Pin|XH1_Pin;
  GPIO_InitStruct.Mode = GPIO_MODE_ANALOG;
  GPIO_InitStruct.Pull = GPIO_PULLDOWN;
  HAL_GPIO_Init(GPIOH, &GPIO_InitStruct);

  /*Configure GPIO pin : CODEC_RESET_Pin */
  GPIO_InitStruct.Pin = CODEC_RESET_Pin;
  GPIO_InitStruct.Mode = GPIO_MODE_OUTPUT_PP;
  GPIO_InitStruct.Pull = GPIO_NOPULL;
  GPIO_InitStruct.Speed = GPIO_SPEED_FREQ_LOW;
  HAL_GPIO_Init(CODEC_RESET_GPIO_Port, &GPIO_InitStruct);

  /*Configure GPIO pins : XB0_Pin XB1_Pin XB2_Pin XB8_Pin
                           XB9_Pin */
  GPIO_InitStruct.Pin = XB0_Pin|XB1_Pin|XB2_Pin|XB8_Pin
                          |XB9_Pin;
  GPIO_InitStruct.Mode = GPIO_MODE_ANALOG;
  GPIO_InitStruct.Pull = GPIO_PULLDOWN;
  HAL_GPIO_Init(GPIOB, &GPIO_InitStruct);

  /*Configure GPIO pins : AUX_OUTPUT_Pin LED_D_Pin LED_C_Pin */
  GPIO_InitStruct.Pin = AUX_OUTPUT_Pin|LED_D_Pin|LED_C_Pin;
  GPIO_InitStruct.Mode = GPIO_MODE_OUTPUT_PP;
  GPIO_InitStruct.Pull = GPIO_NOPULL;
  GPIO_InitStruct.Speed = GPIO_SPEED_FREQ_LOW;
  HAL_GPIO_Init(GPIOD, &GPIO_InitStruct);

  /*Configure GPIO pins : AUX_INPUT_Pin SD_DETECT_Pin BTN_D_Pin BTN_C_Pin */
  GPIO_InitStruct.Pin = AUX_INPUT_Pin|SD_DETECT_Pin|BTN_D_Pin|BTN_C_Pin;
  GPIO_InitStruct.Mode = GPIO_MODE_INPUT;
  GPIO_InitStruct.Pull = GPIO_NOPULL;
  HAL_GPIO_Init(GPIOD, &GPIO_InitStruct);

  /*Configure GPIO pins : XD12_Pin XD13_Pin XD14_Pin XD15_Pin
                           XD0_Pin XD1_Pin */
  GPIO_InitStruct.Pin = XD12_Pin|XD13_Pin|XD14_Pin|XD15_Pin
                          |XD0_Pin|XD1_Pin;
  GPIO_InitStruct.Mode = GPIO_MODE_ANALOG;
  GPIO_InitStruct.Pull = GPIO_PULLDOWN;
  HAL_GPIO_Init(GPIOD, &GPIO_InitStruct);

  /*Configure GPIO pins : XA8_Pin XA10_Pin XA15_Pin */
  GPIO_InitStruct.Pin = XA8_Pin|XA10_Pin|XA15_Pin;
  GPIO_InitStruct.Mode = GPIO_MODE_ANALOG;
  GPIO_InitStruct.Pull = GPIO_PULLDOWN;
  HAL_GPIO_Init(GPIOA, &GPIO_InitStruct);

  /*Configure GPIO pins : BTN_B_Pin BTN_A_Pin */
  GPIO_InitStruct.Pin = BTN_B_Pin|BTN_A_Pin;
  GPIO_InitStruct.Mode = GPIO_MODE_INPUT;
  GPIO_InitStruct.Pull = GPIO_NOPULL;
  HAL_GPIO_Init(GPIOB, &GPIO_InitStruct);

  /*Configure GPIO pins : LED_B_Pin LED_A_Pin LED_RD_Pin */
  GPIO_InitStruct.Pin = LED_B_Pin|LED_A_Pin|LED_RD_Pin;
  GPIO_InitStruct.Mode = GPIO_MODE_OUTPUT_PP;
  GPIO_InitStruct.Pull = GPIO_NOPULL;
  GPIO_InitStruct.Speed = GPIO_SPEED_FREQ_LOW;
  HAL_GPIO_Init(GPIOB, &GPIO_InitStruct);

}

 /* MPU Configuration */

void MPU_Config(void)
{
  MPU_Region_InitTypeDef MPU_InitStruct = {0};

  /* Disables the MPU */
  HAL_MPU_Disable();

  /** Initializes and configures the Region and the memory to be protected
  */
  MPU_InitStruct.Enable = MPU_REGION_ENABLE;
  MPU_InitStruct.Number = MPU_REGION_NUMBER0;
  MPU_InitStruct.BaseAddress = 0x0;
  MPU_InitStruct.Size = MPU_REGION_SIZE_4GB;
  MPU_InitStruct.SubRegionDisable = 0x87;
  MPU_InitStruct.TypeExtField = MPU_TEX_LEVEL0;
  MPU_InitStruct.AccessPermission = MPU_REGION_NO_ACCESS;
  MPU_InitStruct.DisableExec = MPU_INSTRUCTION_ACCESS_DISABLE;
  MPU_InitStruct.IsShareable = MPU_ACCESS_SHAREABLE;
  MPU_InitStruct.IsCacheable = MPU_ACCESS_NOT_CACHEABLE;
  MPU_InitStruct.IsBufferable = MPU_ACCESS_NOT_BUFFERABLE;

  HAL_MPU_ConfigRegion(&MPU_InitStruct);
  /* Enables the MPU */
  HAL_MPU_Enable(MPU_PRIVILEGED_DEFAULT);

}

void Error_Handler(void)
{
  __disable_irq();
  while (1)
  {
  }
}
